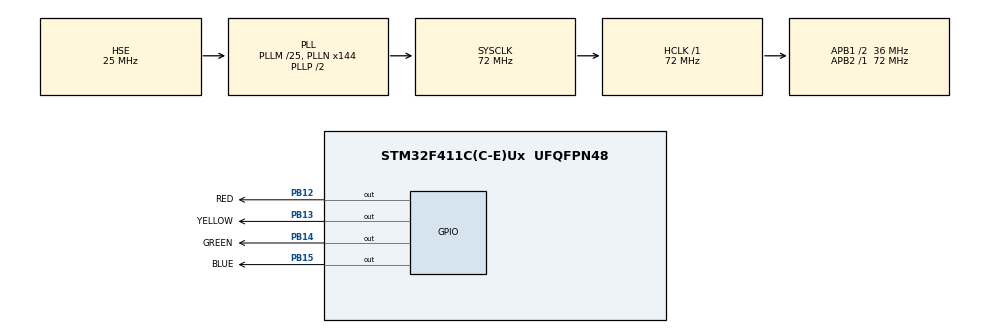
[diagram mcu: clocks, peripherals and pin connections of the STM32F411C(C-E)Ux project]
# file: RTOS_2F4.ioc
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FREERTOS.Tasks01=defaultTask,24,128,StartDefaultTask,Default,NULL,Dynamic,NULL,NULL;FlashGreenTask,24,128,FlashGreen,Default,NULL,Dynamic,NULL,NULL;FlashRedTask,32,128,FlashRed,Default,NULL,Dynamic,NULL,NULL
FREERTOS.configTOTAL_HEAP_SIZE=3600
Mcu.Family=STM32F4
Mcu.Name=STM32F411C(C-E)Ux
Mcu.Package=UFQFPN48
NVIC.PriorityGroup=NVIC_PRIORITYGROUP_4
NVIC.TIM4_IRQn=true\:15\:0\:false\:false\:true\:false\:false\:true\:true
NVIC.TimeBase=TIM4_IRQn
NVIC.TimeBaseIP=TIM4
PB12.GPIO_Label=RED
PB12.Signal=GPIO_Output
PB13.GPIO_Label=YELLOW
PB13.Signal=GPIO_Output
PB14.GPIO_Label=GREEN
PB14.Signal=GPIO_Output
PB15.GPIO_Label=BLUE
PB15.Signal=GPIO_Output
PH0\ -\ OSC_IN.Mode=HSE-External-Oscillator
PH0\ -\ OSC_IN.Signal=RCC_OSC_IN
PH1\ -\ OSC_OUT.Mode=HSE-External-Oscillator
PH1\ -\ OSC_OUT.Signal=RCC_OSC_OUT
ProjectManager.HeapSize=0x200
ProjectManager.StackSize=0x400
ProjectManager.TargetToolchain=STM32CubeIDE
RCC.48MHZClocksFreq_Value=36000000
RCC.AHBFreq_Value=72000000
RCC.APB1CLKDivider=RCC_HCLK_DIV2
RCC.APB1Freq_Value=36000000
RCC.APB1TimFreq_Value=72000000
RCC.APB2Freq_Value=72000000
RCC.APB2TimFreq_Value=72000000
RCC.CortexFreq_Value=72000000
RCC.HCLKFreq_Value=72000000
RCC.HSE_VALUE=25000000
RCC.HSI_VALUE=16000000
RCC.LSE_VALUE=32768
RCC.PLLM=25
RCC.PLLN=144
RCC.PLLSourceVirtual=RCC_PLLSOURCE_HSE
RCC.SYSCLKFreq_VALUE=72000000
RCC.SYSCLKSource=RCC_SYSCLKSOURCE_PLLCLK
RCC.VCOOutputFreq_Value=144000000
VP_FREERTOS_VS_CMSIS_V2.Mode=CMSIS_V2
VP_SYS_VS_tim4.Mode=TIM4
board=custom

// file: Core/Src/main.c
/* USER CODE BEGIN Header */
/**
  ******************************************************************************
  * @file           : main.c
  * @brief          : Main program body
  ******************************************************************************
  * @attention
  *
  * Copyright (c) 2024 STMicroelectronics.
  * All rights reserved.
  *
  * This software is licensed under terms that can be found in the LICENSE file
  * in the root directory of this software component.
  * If no LICENSE file comes with this software, it is provided AS-IS.
  *
  ******************************************************************************
  */
/* USER CODE END Header */
#include "main.h"
#include "cmsis_os.h"

/* Definitions for defaultTask */
osThreadId_t defaultTaskHandle;
const osThreadAttr_t defaultTask_attributes = {
  .name = "defaultTask",
  .stack_size = 128 * 4,
  .priority = (osPriority_t) osPriorityNormal,
};
/* Definitions for FlashGreenTask */
osThreadId_t FlashGreenTaskHandle;
const osThreadAttr_t FlashGreenTask_attributes = {
  .name = "FlashGreenTask",
  .stack_size = 128 * 4,
  .priority = (osPriority_t) osPriorityNormal,
};
/* Definitions for FlashRedTask */
osThreadId_t FlashRedTaskHandle;
const osThreadAttr_t FlashRedTask_attributes = {
  .name = "FlashRedTask",
  .stack_size = 128 * 4,
  .priority = (osPriority_t) osPriorityAboveNormal,
};

void SystemClock_Config(void);
static void MX_GPIO_Init(void);
void StartDefaultTask(void *argument);
void FlashGreen(void *argument);
void FlashRed(void *argument);

int main(void)
{

  /* MCU Configuration--------------------------------------------------------*/

  /* Reset of all peripherals, Initializes the Flash interface and the Systick. */
  HAL_Init();

  /* Configure the system clock */
  SystemClock_Config();

  /* Initialize all configured peripherals */
  MX_GPIO_Init();

  /* Init scheduler */
  osKernelInitialize();

  /* Create the thread(s) */
  /* creation of defaultTask */
  defaultTaskHandle = osThreadNew(StartDefaultTask, NULL, &defaultTask_attributes);

  /* creation of FlashGreenTask */
  FlashGreenTaskHandle = osThreadNew(FlashGreen, NULL, &FlashGreenTask_attributes);

  /* creation of FlashRedTask */
  FlashRedTaskHandle = osThreadNew(FlashRed, NULL, &FlashRedTask_attributes);

  /* Start scheduler */
  osKernelStart();

  /* We should never get here as control is now taken by the scheduler */

  /* Infinite loop */
  while (1)
  {

  }
}

void SystemClock_Config(void)
{
  RCC_OscInitTypeDef RCC_OscInitStruct = {0};
  RCC_ClkInitTypeDef RCC_ClkInitStruct = {0};

  /** Configure the main internal regulator output voltage
  */
  __HAL_RCC_PWR_CLK_ENABLE();
  __HAL_PWR_VOLTAGESCALING_CONFIG(PWR_REGULATOR_VOLTAGE_SCALE1);

  /** Initializes the RCC Oscillators according to the specified parameters
  * in the RCC_OscInitTypeDef structure.
  */
  RCC_OscInitStruct.OscillatorType = RCC_OSCILLATORTYPE_HSE;
  RCC_OscInitStruct.HSEState = RCC_HSE_ON;
  RCC_OscInitStruct.PLL.PLLState = RCC_PLL_ON;
  RCC_OscInitStruct.PLL.PLLSource = RCC_PLLSOURCE_HSE;
  RCC_OscInitStruct.PLL.PLLM = 25;
  RCC_OscInitStruct.PLL.PLLN = 144;
  RCC_OscInitStruct.PLL.PLLP = RCC_PLLP_DIV2;
  RCC_OscInitStruct.PLL.PLLQ = 4;
  if (HAL_RCC_OscConfig(&RCC_OscInitStruct) != HAL_OK)
  {
    Error_Handler();
  }

  /** Initializes the CPU, AHB and APB buses clocks
  */
  RCC_ClkInitStruct.ClockType = RCC_CLOCKTYPE_HCLK|RCC_CLOCKTYPE_SYSCLK
                              |RCC_CLOCKTYPE_PCLK1|RCC_CLOCKTYPE_PCLK2;
  RCC_ClkInitStruct.SYSCLKSource = RCC_SYSCLKSOURCE_PLLCLK;
  RCC_ClkInitStruct.AHBCLKDivider = RCC_SYSCLK_DIV1;
  RCC_ClkInitStruct.APB1CLKDivider = RCC_HCLK_DIV2;
  RCC_ClkInitStruct.APB2CLKDivider = RCC_HCLK_DIV1;

  if (HAL_RCC_ClockConfig(&RCC_ClkInitStruct, FLASH_LATENCY_2) != HAL_OK)
  {
    Error_Handler();
  }
}

static void MX_GPIO_Init(void)
{
  GPIO_InitTypeDef GPIO_InitStruct = {0};

  /* GPIO Ports Clock Enable */
  __HAL_RCC_GPIOH_CLK_ENABLE();
  __HAL_RCC_GPIOB_CLK_ENABLE();

  /*Configure GPIO pin Output Level */
  HAL_GPIO_WritePin(GPIOB, RED_Pin|YELLOW_Pin|GREEN_Pin|BLUE_Pin, GPIO_PIN_RESET);

  /*Configure GPIO pins : RED_Pin YELLOW_Pin GREEN_Pin BLUE_Pin */
  GPIO_InitStruct.Pin = RED_Pin|YELLOW_Pin|GREEN_Pin|BLUE_Pin;
  GPIO_InitStruct.Mode = GPIO_MODE_OUTPUT_PP;
  GPIO_InitStruct.Pull = GPIO_NOPULL;
  GPIO_InitStruct.Speed = GPIO_SPEED_FREQ_LOW;
  HAL_GPIO_Init(GPIOB, &GPIO_InitStruct);

}

void StartDefaultTask(void *argument)
{
  for(;;)
  {
    osDelay(1);
  }
}

void FlashGreen(void *argument)
{
  /* USER CODE BEGIN FlashGreen */
  /* Infinite loop */
  for(;;)
  {
	  HAL_GPIO_WritePin(BLUE_GPIO_Port, BLUE_Pin, GPIO_PIN_RESET); // Blue LED ON

	      // 2. Toggle the Green LED for 4 seconds (20 Hz toggle rate)
	      for (int i = 0; i < 8; i++)
	      {
	        HAL_GPIO_TogglePin(GREEN_GPIO_Port, GREEN_Pin); // Toggle Green LED
	        osDelay(500); // Delay 50 ms for 20 Hz
	      }

	      // 3. Turn the Green LED off
	      HAL_GPIO_WritePin(GREEN_GPIO_Port, GREEN_Pin, GPIO_PIN_SET); // Green LED OFF

	      // 4. Turn the Blue LED off
	      HAL_GPIO_WritePin(BLUE_GPIO_Port, BLUE_Pin, GPIO_PIN_SET); // Blue LED OFF

	      // 5. Suspend for 6 seconds
	      osDelay(6000);
  }
  /* USER CODE END FlashGreen */
}

void FlashRed(void *argument)
{
  /* USER CODE BEGIN FlashRed */
  /* Infinite loop */
  for(;;)
  {
	  // 1. Turn the Orange LED on (Active Low)
	      HAL_GPIO_WritePin(YELLOW_GPIO_Port, YELLOW_Pin, GPIO_PIN_RESET); // Orange LED ON

	      // 2. Toggle the Red LED for 0.5 seconds (20 Hz toggle rate)
	      for (int i = 0; i < 10; i++)
	      {
	        HAL_GPIO_TogglePin(RED_GPIO_Port, RED_Pin); // Toggle Red LED
	        osDelay(50); // Delay 50 ms for 20 Hz
	      }

	      // 3. Turn the Red LED off
	      HAL_GPIO_WritePin(RED_GPIO_Port, RED_Pin, GPIO_PIN_SET); // Red LED OFF

	      // 4. Turn the Orange LED off
	      HAL_GPIO_WritePin(YELLOW_GPIO_Port, YELLOW_Pin, GPIO_PIN_SET); // Orange LED OFF

	      // 5. Suspend for 1.5 seconds
	      osDelay(1500);
  }
  /* USER CODE END FlashRed */
}

void HAL_TIM_PeriodElapsedCallback(TIM_HandleTypeDef *htim)
{
  if (htim->Instance == TIM4) {
    HAL_IncTick();
  }
}

void Error_Handler(void)
{
  __disable_irq();
  while (1)
  {
  }
}
